# SoC_TIMESYNC_XBAR1_SOC_TIMESYNC_XBAR1_INTR_ROUTER_CFG_52E04000h register map
Vendor: Texas Instruments
Peripheral module from a debugger description file (folder AM263P).
Registers are 32-bit, read-only, reset 0x66948100 unless marked. A register's access mark holds for its fields unless they carry their own. Offsets are as the file gives them; lines under a group give offsets from that group; [hi:lo] are bit positions; {n}, {i} and the like mark numbered series; 'fields as' and 'values as' point back to an identical list; <NAME> marks a mode.

## SoC_TIMESYNC_XBAR1_INTR_ROUTER_CFG
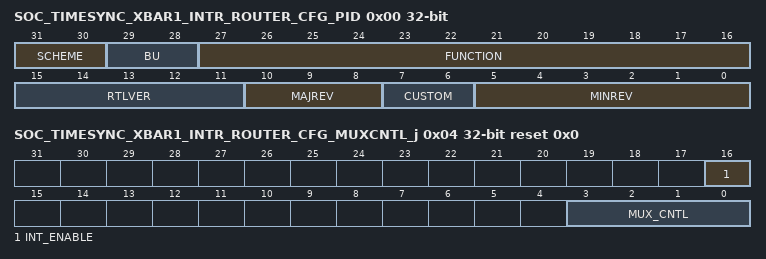
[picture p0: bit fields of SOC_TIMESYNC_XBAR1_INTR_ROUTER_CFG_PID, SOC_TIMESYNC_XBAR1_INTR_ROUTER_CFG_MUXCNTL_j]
0x00 SOC_TIMESYNC_XBAR1_INTR_ROUTER_CFG_PID — Identification register.
  [31:30] SCHEME
  [29:28] BU
  [27:16] FUNCTION
  [15:11] RTLVER — Rtl version
  [10:8] MAJREV — major version
  [7:6] CUSTOM — custom id
  [5:0] MINREV — minor version
0x04 SOC_TIMESYNC_XBAR1_INTR_ROUTER_CFG_MUXCNTL_j rw reset 0x0 — Interrupt mux control register.
  [16] INT_ENABLE — Interrupt j Output Enable.
  [3:0] MUX_CNTL — Mux Control for Interrupt j.
